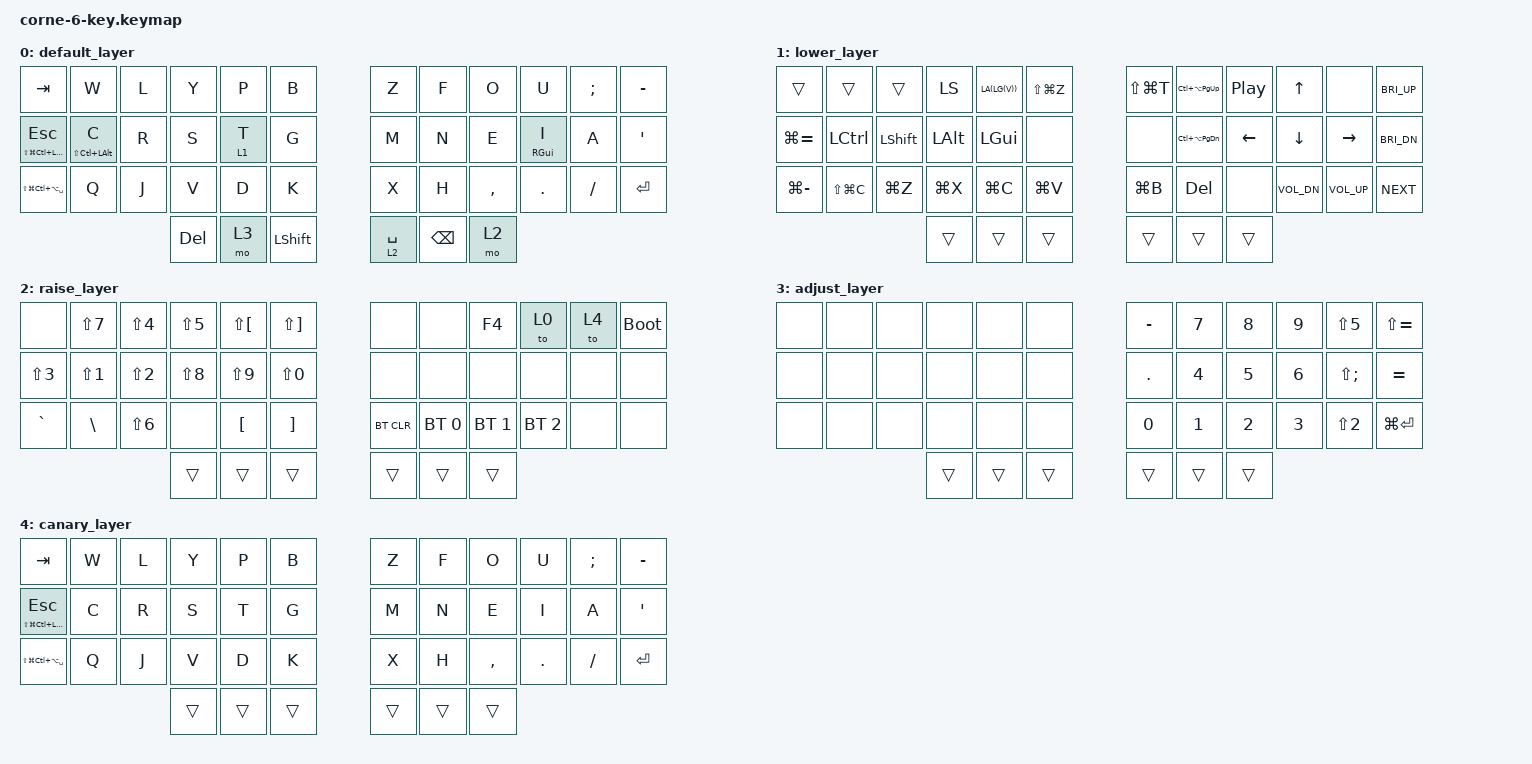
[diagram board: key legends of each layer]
/*
 * Copyright (c) 2020 The ZMK Contributors
 *
 * SPDX-License-Identifier: MIT
 */

#include <behaviors.dtsi>
#include <dt-bindings/zmk/keys.h>
#include <dt-bindings/zmk/bt.h>

#include "../zmk-nodefree-config/helper.h"
#include "../zmk-nodefree-config/keypos_def/keypos_42keys.h"
#define KEYS_L LT0 LT1 LT2 LT3 LT4 LT5 LM0 LM1 LM2 LM3 LM4 LM5 LB0 LB1 LB2 LB3 LB4 LB5
#define KEYS_R RT0 RT1 RT2 RT3 RT4 RT5 RM0 RM1 RM2 RM3 RM4 RM5 RB0 RB1 RB2 RB3 RB4 RB5
#define KEYS_T LH2 LH1 LH0 RH0 RH1 RH2

#undef COMBO_HOOK
#define COMBO_HOOK require-prior-idle-ms = <150>;

#define HM_TAPPING_TERM 350

#define DEFAULT 0
#define LOWER   1
#define RAISE   2
#define ADJUST  3
#define CANARY  4

//shortcuts
#define HYPESC &gqt LS(LG(LC(LALT))) ESC
#define RAYCAST &kp LS(LG(LC(LA(SPACE))))
#define MEHC &gqt LS(LC(LALT)) C
#define DELWORD &kp LA(BSPC)
#define HYPSPC &gqt LS(LG(LC(LALT))) SPACE

#define XXX &none
#define ___ &trans

&lt {  // layer-tap config
    flavor = "tap-preferred";
    tapping-term-ms = <250>;
};

//┌────────┬────────┬────────┬────────┬────────┬────────┐                          ┌────────┬────────┬────────┬────────┬────────┬────────┐
//     0       1        2        3        4        5                                   6        7        8        9        10       11
//├────────┼────────┼────────┼────────┼────────┼────────┤                          ├────────┼────────┼────────┼────────┼────────┼────────┤
//    12       13       14       15       16       17                                  18       19       20       21       22       23
//├────────┼────────┼────────┼────────┼────────┼────────┤                          ├────────┼────────┼────────┼────────┼────────┼────────┤
//    24       25       26       27       28       29                                  30       31       32       33       34       35
//└────────┴────────┴────────┴───┬────┴───┬────┴───┬────┘                          └───┬────┴───┬────┴───┬────┴────────┴────────┴────────┘
//                                   36       37       38                        39       40        41
                              // └────────┴────────┴────────┘                 └────────┴────────┴────────┘

/ {
    macros {
        auto_brackets: auto_brackets {
            label = "auto_brackets";
            compatible = "zmk,behavior-macro";
            #binding-cells = <0>;
            bindings
                = <&kp LS(N9)>
                , <&kp LS(N0)>
                , <&kp LEFT>
                ;
        };
        selall_copy: selall_copy {
            label = "selall_copy";
            compatible = "zmk,behavior-macro";
            #binding-cells = <0>;
            bindings
                = <&kp LG(A)>
                , <&kp LG(C)>
                ;
        };
    };

    combos {
        compatible = "zmk,combos";
//homerow app        
        combo_find {
            timeout-ms = <35>;
            key-positions = <31 32 33>;
            require-prior-idle-ms = <150>;
            bindings = <&kp LA(LS(LC(S)))>;
        };
//back
        combo_back {
            timeout-ms = <35>;
            key-positions = <13 14 15>;
            require-prior-idle-ms = <150>;
            bindings = <&kp LG(LBKT)>;
        };
//find        
        combo_fwds {
            timeout-ms = <35>;
            key-positions = <14 15 16>;
            require-prior-idle-ms = <150>;
            bindings = <&kp LG(F)>;

        };
//autobracket        
        combo_brackets {
            timeout-ms = <35>;
            key-positions = <19 20 21>;
            require-prior-idle-ms = <150>;
            bindings = <&auto_brackets>;
        };
        combo_cmdComma {
            timeout-ms = <35>;
            key-positions = <6 18>;
            require-prior-idle-ms = <150>;
            bindings = <&kp LG(COMMA)>;
        };
        combo_cmdK {
            timeout-ms = <35>;
            key-positions = <7 8 9>;
            require-prior-idle-ms = <150>;
            bindings = <&kp LG(K)>;
        };
        combo_minimize {
            timeout-ms = <35>;
            key-positions = <1 2 3>;
            require-prior-idle-ms = <150>;
            bindings = <&kp LG(M)>;
        };
        combo_undo {
            timeout-ms = <35>;
            key-positions = <25 26>;
            require-prior-idle-ms = <150>;
            bindings = <&kp LG(Z)>;
        };
        combo_copy {
            timeout-ms = <35>;
            key-positions = <26 27>;
            require-prior-idle-ms = <150>;
            bindings = <&kp LG(C)>;
        };
        combo_paste {
            timeout-ms = <35>;
            key-positions = <26 28>;
            require-prior-idle-ms = <150>;
            bindings = <&kp LG(V)>;
        };
        combo_cut {
            timeout-ms = <35>;
            key-positions = <25 27>;
            require-prior-idle-ms = <150>;
            bindings = <&kp LG(X)>;
        };
        combo_selall {
            timeout-ms = <35>;
            key-positions = <25 29>;
            require-prior-idle-ms = <150>;
            bindings = <&kp LG(A)>;
        };
        combo_cmdL {
            timeout-ms = <35>;
            key-positions = <20 21 22>;
            require-prior-idle-ms = <150>;
            bindings = <&kp LG(L)>;
        };
        combo_cmdO {
            timeout-ms = <35>;
            key-positions = <6 8>;
            require-prior-idle-ms = <150>;
            bindings = <&kp LG(O)>;
        };
        combo_cmdN {
            timeout-ms = <35>;
            key-positions = <6 19>;
            require-prior-idle-ms = <150>;
            bindings = <&kp LG(N)>;
        };
        combo_cmdW {
            timeout-ms = <35>;
            key-positions = <2 3 4>;
            require-prior-idle-ms = <150>;
            bindings = <&kp LG(W)>;
        };
        combo_cmdR {
            timeout-ms = <35>;
            key-positions = <3 4 5>;
            require-prior-idle-ms = <150>;
            bindings = <&kp LG(R)>;
        };
//hyper hyphen        
        combo_cmdHyphen {
            timeout-ms = <35>;
            key-positions = <5 17>;
            require-prior-idle-ms = <150>;
            bindings = <&kp LA(LC(LS(LG(MINUS))))>;
        };
        combo_cmdS {
            timeout-ms = <35>;
            key-positions = <17 29>;
            require-prior-idle-ms = <150>;
            bindings = <&kp LG(S)>;
        };
        combo_cmdQ {
            timeout-ms = <35>;
            key-positions = <1 10>;
            require-prior-idle-ms = <150>;
            bindings = <&kp LG(Q)>;
        };
    };

    behaviors {
        gqt: require-prior-idle {
            compatible = "zmk,behavior-hold-tap";
            label = "GLOBAL_QUICK_TAP";
            #binding-cells = <2>;
            flavor = "tap-preferred";
            tapping-term-ms = <250>;
            quick-tap-ms = <175>;                // repeat on tap-into-hold
            require-prior-idle-ms = <75>;         // requires PR #1387
            bindings = <&kp>, <&kp>;
        };
        gqt_l: thumb_right_hold {
            compatible = "zmk,behavior-hold-tap";
            label = "GLOBAL_QUICK_TAP_SPACE";
            #binding-cells = <2>;
            flavor = "balanced";
            tapping-term-ms = <HM_TAPPING_TERM>;
            quick-tap-ms = <175>;                // repeat on tap-into-hold
            require-prior-idle-ms = <15>;         // requires PR #1387
            bindings = <&mo>, <&kp>;
        };
        hr_l: homerow_mods_left {
            compatible = "zmk,behavior-hold-tap";
            label = "HOMEROW_MODS_LEFT";
            #binding-cells = <2>;
            bindings = <&kp>,  <&kp>;

            flavor = "balanced";
            tapping-term-ms = <HM_TAPPING_TERM>;
            quick-tap-ms = <175>;                // repeat on tap-into-hold
            require-prior-idle-ms = <75>;         // requires PR #1387
            hold-trigger-key-positions = <KEYS_R KEYS_T>;
            hold-trigger-on-release;             // requires PR #1423
        };
        hr_r: homerow_mods_right {
            compatible = "zmk,behavior-hold-tap";
            label = "HOMEROW_MODS_RIGHT";
            #binding-cells = <2>;
            bindings = <&kp>, <&kp>;

            flavor = "balanced";
            tapping-term-ms = <HM_TAPPING_TERM>;
            quick_tap_ms = <175>;
            require-prior-idle-ms = <75>;         // requires PR #1387
            hold-trigger-key-positions = <KEYS_L KEYS_T>;
            hold-trigger-on-release;             // requires PR #1423
        };
        hl_l: homerow_layers_left {
            compatible = "zmk,behavior-hold-tap";
            label = "HOMEROW_LAYERS_LEFT";
            #binding-cells = <2>;
            bindings = <&mo>,  <&kp>;

            flavor = "balanced";
            tapping-term-ms = <HM_TAPPING_TERM>;
            quick-tap-ms = <175>;                // repeat on tap-into-hold
            require-prior-idle-ms = <75>;         // requires PR #1387
            hold-trigger-key-positions = <KEYS_R KEYS_T>;
            hold-trigger-on-release;             // requires PR #1423
        };
        hl_r: homerow_layers_right {
            compatible = "zmk,behavior-hold-tap";
            label = "HOMEROW_LAYERS_RIGHT";
            #binding-cells = <2>;
            bindings = <&mo>, <&kp>;

            flavor = "balanced";
            tapping-term-ms = <HM_TAPPING_TERM>;
            quick_tap_ms = <175>;
            require-prior-idle-ms = <75>;         // requires PR #1387
            hold-trigger-key-positions = <KEYS_L KEYS_T>;
            hold-trigger-on-release;             // requires PR #1423
        };
    };

        keymap {
                compatible = "zmk,keymap";

                default_layer {
                        bindings = <
//canary


//┌────────┬────────┬────────┬─────────┬──────────┬────────┐                          ┌────────┬──────────┬─────────┬────────────┬──────────┬─────────┐
   &kp TAB  &kp W    &kp L    &kp Y      &kp P      &kp B                              &kp Z    &kp F      &kp O     &kp U         &kp SEMI   &kp MINUS
//├────────┼────────┼────────┼─────────┼──────────┼────────┤                          ├────────┼──────────┼─────────┼────────────┼──────────┼─────────┤
   HYPESC   MEHC     &kp R    &kp S     &hl_l 1 T  &kp G                               &kp M    &kp N      &kp E     &hr_r RGUI I  &kp A      &kp SQT
//├────────┼────────┼────────┼─────────┼──────────┼────────┤                          ├────────┼──────────┼─────────┼────────────┼──────────┼─────────┤
   RAYCAST  &kp Q    &kp J    &kp V      &kp D      &kp K                              &kp X    &kp H      &kp COMMA &kp DOT       &kp FSLH   &kp RET
//└────────┴────────┴────────┴───┬──-──┴──-─┬─-───┴───┬────┘                          └───┬────┴───┬──────┴───┬─────┴────────────┴──────────┴─────────┘  
                                   &kp DEL &mo 3    &kp LSHFT                    &gqt_l 2 SPACE &kp BSPC &mo 2 
                                // └────────┴────────┴────────┘                 └────────┴────────┴────────┘


                        >;
                };
                lower_layer {
                        bindings = <
// layer 1 - left index

//┌────────┬────────┬────────┬────────┬────────┬────────┐                          ┌────────┬────────┬────────┬────────┬────────┬────────┐
   ___   ___   ___   &kp LS(LA(LG(V))) &kp LS(LG(Z)) &kp LS(LG(T))        &kp LC(LA(PG_UP))  &kp C_PP &kp UP   XXX       &kp C_BRI_UP  &kp LG(EQUAL)
//├────────┼────────┼────────┼────────┼────────┼────────┤                          ├────────┼────────┼────────┼────────┼────────┼────────┤
&kp LCTRL &kp LSHFT &kp LALT &kp LGUI  XXX      XXX                       &kp LC(LA(PG_DN))  &kp LEFT &kp DOWN &kp RIGHT &kp C_BRI_DN  &kp LG(MINUS)
//├────────┼────────┼────────┼────────┼────────┼────────┤                          ├────────┼────────┼────────┼────────┼────────┼────────┤
&kp LS(LG(C)) &kp LG(Z) &kp LG(X) &kp LG(C) &kp LG(V) &kp LG(B)                 &kp DEL      XXX      &kp C_VOL_DN &kp C_VOL_UP &kp C_NEXT  ___
//└────────┴────────┴────────┴───┬────┴───┬────┴───┬────┘                          └───┬────┴───┬────┴───┬────┴────────┴────────┴────────┘
                                    ___      ___       ___                       ___            ___
                                // └────────┴────────┴────────┘                 └────────┴────────┴────────┘
                        >;
                };

                raise_layer {
                        bindings = <

// layer 2 - right thumb

//┌────────┬────────┬────────┬────────┬────────┬────────┐                          ┌────────┬────────┬────────┬────────┬────────┬────────┐
   XXX     &kp LS(N7) &kp LS(N4) &kp LS(N5) &kp LS(LBKT) &kp LS(RBKT)               XXX      XXX      &kp F4   &to 0    &to 4      &bootloader
//├────────┼────────┼────────┼────────┼────────┼────────┤                          ├────────┼────────┼────────┼────────┼────────┼────────┤
&kp LS(N3) &kp LS(N1) &kp LS(N2) &kp LS(N8) &kp LS(N9)   &kp LS(N0)                 XXX      XXX      XXX      XXX      XXX      XXX
//├────────┼────────┼────────┼────────┼────────┼────────┤                          ├────────┼────────┼────────┼────────┼────────┼────────┤
&kp GRAVE  &kp BSLH   &kp LS(N6) XXX        &kp LBKT     &kp RBKT                &bt BT_CLR &bt BT_SEL 0 &bt BT_SEL 1 &bt BT_SEL 2 XXX XXX
//└────────┴────────┴────────┴───┬────┴───┬────┴───┬────┘                          └───┬────┴───┬────┴───┬────┴────────┴────────┴────────┘
                                    ___      ___       ___                       ___      ___      ___
                                // └────────┴────────┴────────┘                 └────────┴────────┴────────┘
                        >;
                };

                adjust_layer {
                        bindings = <                    
// layer 3 - left thumb

//┌────────┬────────┬────────┬────────┬────────┬────────┐                          ┌────────┬────────┬────────┬────────┬────────┬────────┐
   XXX      XXX      XXX      XXX      XXX      XXX                                &kp MINUS &kp N7   &kp N8   &kp N9   &kp LS(N5)       &kp LS(EQUAL)
//├────────┼────────┼────────┼────────┼────────┼────────┤                          ├────────┼────────┼────────┼────────┼────────┼────────┤
   XXX      XXX      XXX      XXX      XXX      XXX                                 &kp DOT  &kp N4   &kp N5   &kp N6   &kp LS(SEMI)     &kp EQUAL
//├────────┼────────┼────────┼────────┼────────┼────────┤                          ├────────┼────────┼────────┼────────┼────────┼────────┤
   XXX      XXX      XXX      XXX      XXX      XXX                                 &kp N0   &kp N1   &kp N2   &kp N3   &kp LS(N2)       &kp LG(RET)
//└────────┴────────┴────────┴───┬────┴───┬────┴───┬────┘                          └───┬────┴───┬────┴───┬────┴────────┴────────┴────────┘
                                    ___      ___       ___                       ___      ___      ___
                                // └────────┴────────┴────────┘                 └────────┴────────┴────────┘
                        >;
                };

                canary_layer {
                        bindings = <                    

//┌────────┬────────┬────────┬────────┬────────┬────────┐                          ┌────────┬────────┬────────┬────────┬────────┬────────┐
   &kp TAB  &kp W    &kp L    &kp Y    &kp P    &kp B                               &kp Z    &kp F    &kp O    &kp U    &kp SEMI &kp MINUS
//├────────┼────────┼────────┼────────┼────────┼────────┤                          ├────────┼────────┼────────┼────────┼────────┼────────┤
   HYPESC   &kp C    &kp R    &kp S    &kp T    &kp G                               &kp M    &kp N    &kp E    &kp I    &kp A    &kp SQT
//├────────┼────────┼────────┼────────┼────────┼────────┤                          ├────────┼────────┼────────┼────────┼────────┼────────┤
   RAYCAST  &kp Q    &kp J    &kp V    &kp D    &kp K                               &kp X    &kp H    &kp COMMA &kp DOT &kp FSLH &kp RET
//└────────┴────────┴────────┴───┬────┴───┬────┴───┬────┘                          └───┬────┴───┬────┴───┬────┴────────┴────────┴────────┘  
                                    ___      ___       ___                       ___      ___      ___
                                // └────────┴────────┴────────┘                 └────────┴────────┴────────┘
                        >;
                };
        };
};
